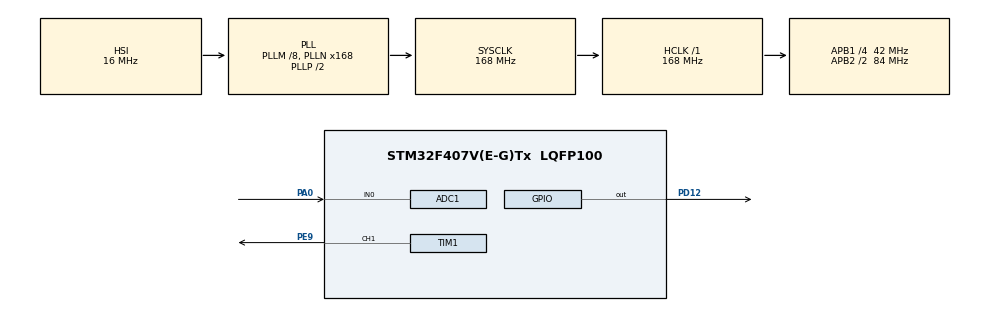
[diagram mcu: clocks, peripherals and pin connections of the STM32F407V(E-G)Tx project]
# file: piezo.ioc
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ADC1.Channel-0\#ChannelRegularConversion=ADC_CHANNEL_0
ADC1.ClockPrescaler=ADC_CLOCK_SYNC_PCLK_DIV4
ADC1.NbrOfConversionFlag=1
ADC1.Rank-0\#ChannelRegularConversion=1
ADC1.SamplingTime-0\#ChannelRegularConversion=ADC_SAMPLETIME_3CYCLES
ADC1.master=1
Mcu.Family=STM32F4
Mcu.Name=STM32F407V(E-G)Tx
Mcu.Package=LQFP100
NVIC.PriorityGroup=NVIC_PRIORITYGROUP_0
PA0-WKUP.Signal=ADCx_IN0
PD12.Signal=GPIO_Output
PE9.Signal=S_TIM1_CH1
ProjectManager.HeapSize=0x200
ProjectManager.StackSize=0x400
ProjectManager.TargetToolchain=SW4STM32
RCC.48MHZClocksFreq_Value=48000000
RCC.AHBFreq_Value=168000000
RCC.APB1CLKDivider=RCC_HCLK_DIV4
RCC.APB1Freq_Value=42000000
RCC.APB1TimFreq_Value=84000000
RCC.APB2CLKDivider=RCC_HCLK_DIV2
RCC.APB2Freq_Value=84000000
RCC.APB2TimFreq_Value=168000000
RCC.CortexFreq_Value=168000000
RCC.HCLKFreq_Value=168000000
RCC.HSE_VALUE=8000000
RCC.HSI_VALUE=16000000
RCC.LSE_VALUE=32768
RCC.PLLM=8
RCC.PLLN=168
RCC.PLLQ=7
RCC.SYSCLKFreq_VALUE=168000000
RCC.SYSCLKSource=RCC_SYSCLKSOURCE_PLLCLK
RCC.VCOOutputFreq_Value=336000000
SH.ADCx_IN0.0=ADC1_IN0,IN0
SH.S_TIM1_CH1.0=TIM1_CH1,PWM Generation1 CH1
TIM1.Channel-PWM\ Generation1\ CH1=TIM_CHANNEL_1
TIM1.Period=2000
TIM1.Prescaler=16
VP_TIM1_VS_ClockSourceINT.Mode=Internal
board=STM32F407G-DISC1

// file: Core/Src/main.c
/* USER CODE BEGIN Header */
/**
  ******************************************************************************
  * @file           : main.c
  * @brief          : Main program body
  ******************************************************************************
  * @attention
  *
  * <h2><center>&copy; Copyright (c) 2021 STMicroelectronics.
  * All rights reserved.</center></h2>
  *
  * This software component is licensed by ST under BSD 3-Clause license,
  * the "License"; You may not use this file except in compliance with the
  * License. You may obtain a copy of the License at:
  *                        opensource.org/licenses/BSD-3-Clause
  *
  ******************************************************************************
  */
/* USER CODE END Header */
#include "main.h"

/* USER CODE BEGIN PD */
#define AVR_LEN 8
#define PWM_FREQUENCY 84000000
#define SOUND_FREQUENCY 20
#define COUNTER_LIMIT 2000
#define SMOOTH_ALPHA 0.03f
/* USER CODE END PD */

ADC_HandleTypeDef hadc1;

TIM_HandleTypeDef htim1;

/* USER CODE BEGIN PV */
uint32_t adc_meassurment;
uint32_t counter = 0;
uint32_t meassurments[AVR_LEN];
uint32_t average = 0;
double adc_smothed;
double adc_smothed_last;
/* USER CODE END PV */

void SystemClock_Config(void);
static void MX_GPIO_Init(void);
static void MX_ADC1_Init(void);
static void MX_TIM1_Init(void);
/* USER CODE BEGIN PFP */
void move_by_one(uint32_t *values, uint32_t lenght){
    for(uint32_t i = 0; i < lenght-1; i++){
        values[i] = values[i+1];
    }
}

uint32_t get_average(uint32_t *values, uint32_t lenght){
    uint32_t average = 0;
    for (int i = 0; i < lenght; ++i) {
        average += values[i];
    }
    return average/lenght;
}
/* USER CODE END PFP */

int main(void)
{
  /* USER CODE BEGIN 1 */
    int touch_flag = 0;
  /* USER CODE END 1 */

  /* MCU Configuration--------------------------------------------------------*/

  /* Reset of all peripherals, Initializes the Flash interface and the Systick. */
  HAL_Init();

  /* Configure the system clock */
  SystemClock_Config();

  /* Initialize all configured peripherals */
  MX_GPIO_Init();
  MX_ADC1_Init();
  MX_TIM1_Init();
  /* USER CODE BEGIN 2 */
  HAL_ADC_Start(&hadc1);
  HAL_TIM_PWM_Start(&htim1, TIM_CHANNEL_1);
  __HAL_TIM_SET_COMPARE(&htim1, TIM_CHANNEL_1, 1000);
  /* USER CODE END 2 */

  /* Infinite loop */
  /* USER CODE BEGIN WHILE */
  while (1)
  {
      if(HAL_ADC_PollForConversion(&hadc1,10) == HAL_OK){
        adc_meassurment = HAL_ADC_GetValue(&hadc1);
        HAL_ADC_Start(&hadc1);
        move_by_one(meassurments, AVR_LEN);
        meassurments[AVR_LEN-1] = adc_meassurment;
        average = get_average(meassurments, AVR_LEN);
        adc_smothed = SMOOTH_ALPHA * (double)get_average(meassurments, AVR_LEN) + (1-SMOOTH_ALPHA) * adc_smothed_last;
        adc_smothed_last = adc_smothed;
      }
      if(adc_meassurment >= 1300 && touch_flag == 0) {
          if(HAL_GPIO_ReadPin(GPIOD, GPIO_PIN_12) == GPIO_PIN_RESET)
            HAL_GPIO_WritePin(GPIOD, GPIO_PIN_12, GPIO_PIN_SET);
          else
              HAL_GPIO_WritePin(GPIOD, GPIO_PIN_12, GPIO_PIN_RESET);
          touch_flag = 1;
      } else if(adc_meassurment <= 300) {
          touch_flag = 0;
      }
    /* USER CODE END WHILE */

  }
}

void SystemClock_Config(void)
{
  RCC_OscInitTypeDef RCC_OscInitStruct = {0};
  RCC_ClkInitTypeDef RCC_ClkInitStruct = {0};

  /** Configure the main internal regulator output voltage
  */
  __HAL_RCC_PWR_CLK_ENABLE();
  __HAL_PWR_VOLTAGESCALING_CONFIG(PWR_REGULATOR_VOLTAGE_SCALE1);
  /** Initializes the RCC Oscillators according to the specified parameters
  * in the RCC_OscInitTypeDef structure.
  */
  RCC_OscInitStruct.OscillatorType = RCC_OSCILLATORTYPE_HSI;
  RCC_OscInitStruct.HSIState = RCC_HSI_ON;
  RCC_OscInitStruct.HSICalibrationValue = RCC_HSICALIBRATION_DEFAULT;
  RCC_OscInitStruct.PLL.PLLState = RCC_PLL_ON;
  RCC_OscInitStruct.PLL.PLLSource = RCC_PLLSOURCE_HSI;
  RCC_OscInitStruct.PLL.PLLM = 8;
  RCC_OscInitStruct.PLL.PLLN = 168;
  RCC_OscInitStruct.PLL.PLLP = RCC_PLLP_DIV2;
  RCC_OscInitStruct.PLL.PLLQ = 7;
  if (HAL_RCC_OscConfig(&RCC_OscInitStruct) != HAL_OK)
  {
    Error_Handler();
  }
  /** Initializes the CPU, AHB and APB buses clocks
  */
  RCC_ClkInitStruct.ClockType = RCC_CLOCKTYPE_HCLK|RCC_CLOCKTYPE_SYSCLK
                              |RCC_CLOCKTYPE_PCLK1|RCC_CLOCKTYPE_PCLK2;
  RCC_ClkInitStruct.SYSCLKSource = RCC_SYSCLKSOURCE_PLLCLK;
  RCC_ClkInitStruct.AHBCLKDivider = RCC_SYSCLK_DIV1;
  RCC_ClkInitStruct.APB1CLKDivider = RCC_HCLK_DIV4;
  RCC_ClkInitStruct.APB2CLKDivider = RCC_HCLK_DIV2;

  if (HAL_RCC_ClockConfig(&RCC_ClkInitStruct, FLASH_LATENCY_5) != HAL_OK)
  {
    Error_Handler();
  }
}

static void MX_ADC1_Init(void)
{

  ADC_ChannelConfTypeDef sConfig = {0};

  /** Configure the global features of the ADC (Clock, Resolution, Data Alignment and number of conversion)
  */
  hadc1.Instance = ADC1;
  hadc1.Init.ClockPrescaler = ADC_CLOCK_SYNC_PCLK_DIV4;
  hadc1.Init.Resolution = ADC_RESOLUTION_12B;
  hadc1.Init.ScanConvMode = DISABLE;
  hadc1.Init.ContinuousConvMode = DISABLE;
  hadc1.Init.DiscontinuousConvMode = DISABLE;
  hadc1.Init.ExternalTrigConvEdge = ADC_EXTERNALTRIGCONVEDGE_NONE;
  hadc1.Init.ExternalTrigConv = ADC_SOFTWARE_START;
  hadc1.Init.DataAlign = ADC_DATAALIGN_RIGHT;
  hadc1.Init.NbrOfConversion = 1;
  hadc1.Init.DMAContinuousRequests = DISABLE;
  hadc1.Init.EOCSelection = ADC_EOC_SINGLE_CONV;
  if (HAL_ADC_Init(&hadc1) != HAL_OK)
  {
    Error_Handler();
  }
  /** Configure for the selected ADC regular channel its corresponding rank in the sequencer and its sample time.
  */
  sConfig.Channel = ADC_CHANNEL_0;
  sConfig.Rank = 1;
  sConfig.SamplingTime = ADC_SAMPLETIME_3CYCLES;
  if (HAL_ADC_ConfigChannel(&hadc1, &sConfig) != HAL_OK)
  {
    Error_Handler();
  }

}

static void MX_TIM1_Init(void)
{

  TIM_ClockConfigTypeDef sClockSourceConfig = {0};
  TIM_MasterConfigTypeDef sMasterConfig = {0};
  TIM_OC_InitTypeDef sConfigOC = {0};
  TIM_BreakDeadTimeConfigTypeDef sBreakDeadTimeConfig = {0};

  /* USER CODE BEGIN TIM1_Init 1 */
    htim1.Init.Prescaler =2* PWM_FREQUENCY / SOUND_FREQUENCY / COUNTER_LIMIT;
  /* USER CODE END TIM1_Init 1 */
  htim1.Instance = TIM1;
  //htim1.Init.Prescaler = 16;
  htim1.Init.CounterMode = TIM_COUNTERMODE_UP;
  htim1.Init.Period = 2000;
  htim1.Init.ClockDivision = TIM_CLOCKDIVISION_DIV1;
  htim1.Init.RepetitionCounter = 0;
  htim1.Init.AutoReloadPreload = TIM_AUTORELOAD_PRELOAD_DISABLE;
  if (HAL_TIM_Base_Init(&htim1) != HAL_OK)
  {
    Error_Handler();
  }
  sClockSourceConfig.ClockSource = TIM_CLOCKSOURCE_INTERNAL;
  if (HAL_TIM_ConfigClockSource(&htim1, &sClockSourceConfig) != HAL_OK)
  {
    Error_Handler();
  }
  if (HAL_TIM_PWM_Init(&htim1) != HAL_OK)
  {
    Error_Handler();
  }
  sMasterConfig.MasterOutputTrigger = TIM_TRGO_RESET;
  sMasterConfig.MasterSlaveMode = TIM_MASTERSLAVEMODE_DISABLE;
  if (HAL_TIMEx_MasterConfigSynchronization(&htim1, &sMasterConfig) != HAL_OK)
  {
    Error_Handler();
  }
  sConfigOC.OCMode = TIM_OCMODE_PWM1;
  sConfigOC.Pulse = 0;
  sConfigOC.OCPolarity = TIM_OCPOLARITY_HIGH;
  sConfigOC.OCNPolarity = TIM_OCNPOLARITY_HIGH;
  sConfigOC.OCFastMode = TIM_OCFAST_DISABLE;
  sConfigOC.OCIdleState = TIM_OCIDLESTATE_RESET;
  sConfigOC.OCNIdleState = TIM_OCNIDLESTATE_RESET;
  if (HAL_TIM_PWM_ConfigChannel(&htim1, &sConfigOC, TIM_CHANNEL_1) != HAL_OK)
  {
    Error_Handler();
  }
  sBreakDeadTimeConfig.OffStateRunMode = TIM_OSSR_DISABLE;
  sBreakDeadTimeConfig.OffStateIDLEMode = TIM_OSSI_DISABLE;
  sBreakDeadTimeConfig.LockLevel = TIM_LOCKLEVEL_OFF;
  sBreakDeadTimeConfig.DeadTime = 0;
  sBreakDeadTimeConfig.BreakState = TIM_BREAK_DISABLE;
  sBreakDeadTimeConfig.BreakPolarity = TIM_BREAKPOLARITY_HIGH;
  sBreakDeadTimeConfig.AutomaticOutput = TIM_AUTOMATICOUTPUT_DISABLE;
  if (HAL_TIMEx_ConfigBreakDeadTime(&htim1, &sBreakDeadTimeConfig) != HAL_OK)
  {
    Error_Handler();
  }
  HAL_TIM_MspPostInit(&htim1);

}

static void MX_GPIO_Init(void)
{
  GPIO_InitTypeDef GPIO_InitStruct = {0};

  /* GPIO Ports Clock Enable */
  __HAL_RCC_GPIOA_CLK_ENABLE();
  __HAL_RCC_GPIOE_CLK_ENABLE();
  __HAL_RCC_GPIOD_CLK_ENABLE();

  /*Configure GPIO pin Output Level */
  HAL_GPIO_WritePin(GPIOD, GPIO_PIN_12, GPIO_PIN_RESET);

  /*Configure GPIO pin : PD12 */
  GPIO_InitStruct.Pin = GPIO_PIN_12;
  GPIO_InitStruct.Mode = GPIO_MODE_OUTPUT_PP;
  GPIO_InitStruct.Pull = GPIO_NOPULL;
  GPIO_InitStruct.Speed = GPIO_SPEED_FREQ_LOW;
  HAL_GPIO_Init(GPIOD, &GPIO_InitStruct);

}

void Error_Handler(void)
{
  __disable_irq();
  while (1)
  {
  }
}

/************************ (C) COPYRIGHT STMicroelectronics *****END OF FILE****/
